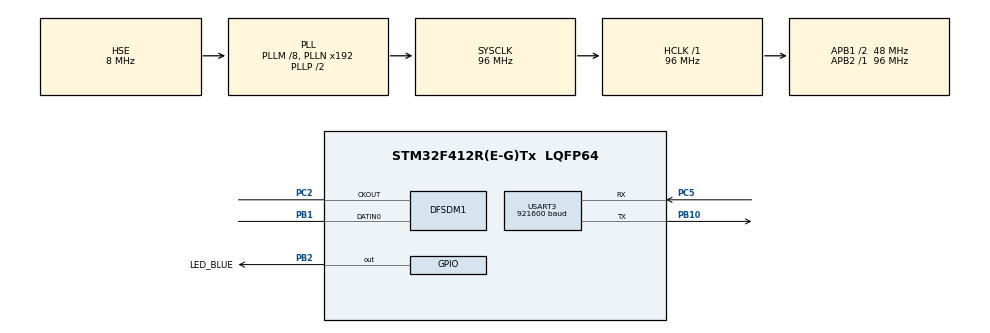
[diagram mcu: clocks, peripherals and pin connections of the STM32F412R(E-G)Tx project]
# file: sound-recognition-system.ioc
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DFSDM1.Divider=30
DFSDM1.DmaMode_reg_FIL0=ENABLE
DFSDM1.FastMode_reg_FIL0=ENABLE
DFSDM1.FilterOrder_CH0=DFSDM_CHANNEL_SINC3_ORDER
DFSDM1.Filter_injChannel0_FIL0=__NULL
DFSDM1.Filter_regChannel_FIL0=DFSDM_CHANNEL_0
DFSDM1.Fosr_FIL0=40
DFSDM1.Iosr_FIL0=5
DFSDM1.RightBitShift_CH0=0x2
DFSDM1.Selection=DFSDM_CHANNEL_OUTPUT_CLOCK_SYSTEM
DFSDM1.SincOrder_FIL0=DFSDM_FILTER_SINC3_ORDER
Dma.DFSDM1_FLT0.0.Direction=DMA_PERIPH_TO_MEMORY
Dma.DFSDM1_FLT0.0.FIFOMode=DMA_FIFOMODE_DISABLE
Dma.DFSDM1_FLT0.0.Instance=DMA2_Stream0
Dma.DFSDM1_FLT0.0.MemDataAlignment=DMA_MDATAALIGN_WORD
Dma.DFSDM1_FLT0.0.MemInc=DMA_MINC_ENABLE
Dma.DFSDM1_FLT0.0.Mode=DMA_CIRCULAR
Dma.DFSDM1_FLT0.0.PeriphDataAlignment=DMA_PDATAALIGN_WORD
Dma.DFSDM1_FLT0.0.PeriphInc=DMA_PINC_DISABLE
Dma.DFSDM1_FLT0.0.Priority=DMA_PRIORITY_VERY_HIGH
Dma.Request0=DFSDM1_FLT0
Dma.Request1=USART3_TX
Dma.USART3_TX.1.Direction=DMA_MEMORY_TO_PERIPH
Dma.USART3_TX.1.FIFOMode=DMA_FIFOMODE_DISABLE
Dma.USART3_TX.1.Instance=DMA1_Stream3
Dma.USART3_TX.1.MemDataAlignment=DMA_MDATAALIGN_BYTE
Dma.USART3_TX.1.MemInc=DMA_MINC_ENABLE
Dma.USART3_TX.1.Mode=DMA_NORMAL
Dma.USART3_TX.1.PeriphDataAlignment=DMA_PDATAALIGN_BYTE
Dma.USART3_TX.1.PeriphInc=DMA_PINC_DISABLE
Dma.USART3_TX.1.Priority=DMA_PRIORITY_LOW
Mcu.Family=STM32F4
Mcu.Name=STM32F412R(E-G)Tx
Mcu.Package=LQFP64
NVIC.DFSDM1_FLT0_IRQn=true\:1\:0\:true\:false\:true\:true\:true\:true
NVIC.DMA1_Stream3_IRQn=true\:5\:0\:true\:false\:true\:false\:true\:true
NVIC.DMA2_Stream0_IRQn=true\:0\:0\:true\:false\:true\:false\:true\:true
NVIC.PriorityGroup=NVIC_PRIORITYGROUP_4
NVIC.USART3_IRQn=true\:6\:0\:true\:false\:true\:false\:true\:true
PA13.Mode=Serial_Wire
PA13.Signal=SYS_JTMS-SWDIO
PA14.Mode=Serial_Wire
PA14.Signal=SYS_JTCK-SWCLK
PB1.Signal=S_DATAIN0DFSDM1
PB10.Mode=Asynchronous
PB10.Signal=USART3_TX
PB2.GPIO_Label=LED_BLUE
PB2.Signal=GPIO_Output
PC14-OSC32_IN.Mode=LSE-External-Oscillator
PC14-OSC32_IN.Signal=RCC_OSC32_IN
PC15-OSC32_OUT.Mode=LSE-External-Oscillator
PC15-OSC32_OUT.Signal=RCC_OSC32_OUT
PC2.GPIO_PuPd=GPIO_NOPULL
PC2.GPIO_Speed=GPIO_SPEED_FREQ_MEDIUM
PC2.Signal=S_CKOUTDFSDM1
PC5.Mode=Asynchronous
PC5.Signal=USART3_RX
PH0\ -\ OSC_IN.Mode=HSE-External-Oscillator
PH0\ -\ OSC_IN.Signal=RCC_OSC_IN
PH1\ -\ OSC_OUT.Mode=HSE-External-Oscillator
PH1\ -\ OSC_OUT.Signal=RCC_OSC_OUT
ProjectManager.HeapSize=0x200
ProjectManager.StackSize=0x400
ProjectManager.TargetToolchain=STM32CubeIDE
RCC.AHBFreq_Value=96000000
RCC.APB1CLKDivider=RCC_HCLK_DIV2
RCC.APB1Freq_Value=48000000
RCC.APB1TimFreq_Value=96000000
RCC.APB2Freq_Value=96000000
RCC.APB2TimFreq_Value=96000000
RCC.CortexFreq_Value=96000000
RCC.EnbaleCSS=true
RCC.HCLKFreq_Value=96000000
RCC.HSE_VALUE=8000000
RCC.PLLI2SM=8
RCC.PLLM=8
RCC.PLLQ=4
RCC.PLLSourceVirtual=RCC_PLLSOURCE_HSE
RCC.RCC_RTC_Clock_Source=RCC_RTCCLKSOURCE_LSE
RCC.RCC_RTC_Clock_SourceVirtual=RCC_RTCCLKSOURCE_LSE
RCC.SYSCLKFreq_VALUE=96000000
RCC.SYSCLKSource=RCC_SYSCLKSOURCE_PLLCLK
RCC.USBFreq_Value=48000000
RCC.VCOOutputFreq_Value=192000000
SH.S_CKOUTDFSDM1.0=DFSDM1_CKOUT,CKOUT
SH.S_CKOUTDFSDM1.1=DFSDM1_CKOUT,PDM_SPI_input_from_ch0_and_internal_clock
SH.S_DATAIN0DFSDM1.0=DFSDM1_DATIN0,PDM_SPI_input_from_ch0_and_internal_clock
USART3.BaudRate=921600
USART3.Mode=MODE_TX_RX
USART3.VirtualMode=VM_ASYNC
VP_CRC_VS_CRC.Mode=CRC_Activate
VP_RTC_VS_RTC_Activate.Mode=RTC_Enabled
VP_RTC_VS_RTC_Calendar.Mode=RTC_Calendar
board=custom

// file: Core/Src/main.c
/* USER CODE BEGIN Header */
/**
  ******************************************************************************
  * @file           : main.c
  * @brief          : Main program body
  ******************************************************************************
  * @attention
  *
  * Copyright (c) 2026 STMicroelectronics.
  * All rights reserved.
  *
  * This software is licensed under terms that can be found in the LICENSE file
  * in the root directory of this software component.
  * If no LICENSE file comes with this software, it is provided AS-IS.
  *
  ******************************************************************************
  */
/* USER CODE END Header */
#include "main.h"
#include "app.h"
#include "indicator.h"

/* USER CODE BEGIN PD */
#define RTC_BACKUP_MAGIC 0x32F2U

/* USER CODE END PD */

CRC_HandleTypeDef hcrc;

DFSDM_Filter_HandleTypeDef hdfsdm1_filter0;
DFSDM_Channel_HandleTypeDef hdfsdm1_channel0;
DMA_HandleTypeDef hdma_dfsdm1_flt0;

RTC_HandleTypeDef hrtc;

UART_HandleTypeDef huart3;
DMA_HandleTypeDef hdma_usart3_tx;

void SystemClock_Config(void);
static void MX_GPIO_Init(void);
static void MX_DMA_Init(void);
static void MX_DFSDM1_Init(void);
static void MX_RTC_Init(void);
static void MX_USART3_UART_Init(void);
static void MX_CRC_Init(void);

int main(void) {

    /* MCU Configuration--------------------------------------------------------*/

    /* Reset of all peripherals, Initializes the Flash interface and the Systick. */
    HAL_Init();

    /* Configure the system clock */
    SystemClock_Config();

    /* Initialize all configured peripherals */
    MX_GPIO_Init();
    MX_DMA_Init();
    MX_DFSDM1_Init();
    MX_RTC_Init();
    MX_USART3_UART_Init();
    MX_CRC_Init();
    /* USER CODE BEGIN 2 */
    app_run();
    /* USER CODE END 2 */

    /* Infinite loop */
    while (1) {

    }
}

void SystemClock_Config(void) {
    RCC_OscInitTypeDef RCC_OscInitStruct = {0};
    RCC_ClkInitTypeDef RCC_ClkInitStruct = {0};

    /** Configure the main internal regulator output voltage
    */
    __HAL_RCC_PWR_CLK_ENABLE();
    __HAL_PWR_VOLTAGESCALING_CONFIG(PWR_REGULATOR_VOLTAGE_SCALE1);

    /** Initializes the RCC Oscillators according to the specified parameters
    * in the RCC_OscInitTypeDef structure.
    */
    RCC_OscInitStruct.OscillatorType = RCC_OSCILLATORTYPE_HSE | RCC_OSCILLATORTYPE_LSE;
    RCC_OscInitStruct.HSEState = RCC_HSE_ON;
    RCC_OscInitStruct.LSEState = RCC_LSE_ON;
    RCC_OscInitStruct.PLL.PLLState = RCC_PLL_ON;
    RCC_OscInitStruct.PLL.PLLSource = RCC_PLLSOURCE_HSE;
    RCC_OscInitStruct.PLL.PLLM = 8;
    RCC_OscInitStruct.PLL.PLLN = 192;
    RCC_OscInitStruct.PLL.PLLP = RCC_PLLP_DIV2;
    RCC_OscInitStruct.PLL.PLLQ = 4;
    RCC_OscInitStruct.PLL.PLLR = 2;
    if (HAL_RCC_OscConfig(&RCC_OscInitStruct) != HAL_OK) {
        Error_Handler();
    }

    /** Initializes the CPU, AHB and APB buses clocks
    */
    RCC_ClkInitStruct.ClockType = RCC_CLOCKTYPE_HCLK | RCC_CLOCKTYPE_SYSCLK
                                  | RCC_CLOCKTYPE_PCLK1 | RCC_CLOCKTYPE_PCLK2;
    RCC_ClkInitStruct.SYSCLKSource = RCC_SYSCLKSOURCE_PLLCLK;
    RCC_ClkInitStruct.AHBCLKDivider = RCC_SYSCLK_DIV1;
    RCC_ClkInitStruct.APB1CLKDivider = RCC_HCLK_DIV2;
    RCC_ClkInitStruct.APB2CLKDivider = RCC_HCLK_DIV1;

    if (HAL_RCC_ClockConfig(&RCC_ClkInitStruct, FLASH_LATENCY_3) != HAL_OK) {
        Error_Handler();
    }

    /** Enables the Clock Security System
    */
    HAL_RCC_EnableCSS();
}

static void MX_CRC_Init(void) {

    hcrc.Instance = CRC;
    if (HAL_CRC_Init(&hcrc) != HAL_OK) {
        Error_Handler();
    }
}

static void MX_DFSDM1_Init(void) {

    hdfsdm1_filter0.Instance = DFSDM1_Filter0;
    hdfsdm1_filter0.Init.RegularParam.Trigger = DFSDM_FILTER_SW_TRIGGER;
    hdfsdm1_filter0.Init.RegularParam.FastMode = ENABLE;
    hdfsdm1_filter0.Init.RegularParam.DmaMode = ENABLE;
    hdfsdm1_filter0.Init.FilterParam.SincOrder = DFSDM_FILTER_SINC3_ORDER;
    hdfsdm1_filter0.Init.FilterParam.Oversampling = 40;
    hdfsdm1_filter0.Init.FilterParam.IntOversampling = 5;
    if (HAL_DFSDM_FilterInit(&hdfsdm1_filter0) != HAL_OK) {
        Error_Handler();
    }
    hdfsdm1_channel0.Instance = DFSDM1_Channel0;
    hdfsdm1_channel0.Init.OutputClock.Activation = ENABLE;
    hdfsdm1_channel0.Init.OutputClock.Selection = DFSDM_CHANNEL_OUTPUT_CLOCK_SYSTEM;
    hdfsdm1_channel0.Init.OutputClock.Divider = 30;
    hdfsdm1_channel0.Init.Input.Multiplexer = DFSDM_CHANNEL_EXTERNAL_INPUTS;
    hdfsdm1_channel0.Init.Input.DataPacking = DFSDM_CHANNEL_STANDARD_MODE;
    hdfsdm1_channel0.Init.Input.Pins = DFSDM_CHANNEL_SAME_CHANNEL_PINS;
    hdfsdm1_channel0.Init.SerialInterface.Type = DFSDM_CHANNEL_SPI_RISING;
    hdfsdm1_channel0.Init.SerialInterface.SpiClock = DFSDM_CHANNEL_SPI_CLOCK_INTERNAL;
    hdfsdm1_channel0.Init.Awd.FilterOrder = DFSDM_CHANNEL_SINC3_ORDER;
    hdfsdm1_channel0.Init.Awd.Oversampling = 1;
    hdfsdm1_channel0.Init.Offset = 0;
    hdfsdm1_channel0.Init.RightBitShift = 0x2;
    if (HAL_DFSDM_ChannelInit(&hdfsdm1_channel0) != HAL_OK) {
        Error_Handler();
    }
    if (HAL_DFSDM_FilterConfigRegChannel(&hdfsdm1_filter0, DFSDM_CHANNEL_0, DFSDM_CONTINUOUS_CONV_ON) != HAL_OK) {
        Error_Handler();
    }
}

static void MX_RTC_Init(void) {

    RTC_TimeTypeDef sTime = {0};
    RTC_DateTypeDef sDate = {0};

    /** Initialize RTC Only
    */
    hrtc.Instance = RTC;
    hrtc.Init.HourFormat = RTC_HOURFORMAT_24;
    hrtc.Init.AsynchPrediv = 127;
    hrtc.Init.SynchPrediv = 255;
    hrtc.Init.OutPut = RTC_OUTPUT_DISABLE;
    hrtc.Init.OutPutPolarity = RTC_OUTPUT_POLARITY_HIGH;
    hrtc.Init.OutPutType = RTC_OUTPUT_TYPE_OPENDRAIN;
    if (HAL_RTC_Init(&hrtc) != HAL_OK) {
        Error_Handler();
    }

    /* USER CODE BEGIN Check_RTC_BKUP */
    if (HAL_RTCEx_BKUPRead(&hrtc, RTC_BKP_DR0) != RTC_BACKUP_MAGIC) {
        /* USER CODE END Check_RTC_BKUP */

        /** Initialize RTC and set the Time and Date
        */
        sTime.Hours = 0x0;
        sTime.Minutes = 0x0;
        sTime.Seconds = 0x0;
        sTime.DayLightSaving = RTC_DAYLIGHTSAVING_NONE;
        sTime.StoreOperation = RTC_STOREOPERATION_RESET;
        if (HAL_RTC_SetTime(&hrtc, &sTime, RTC_FORMAT_BCD) != HAL_OK) {
            Error_Handler();
        }
        sDate.WeekDay = RTC_WEEKDAY_MONDAY;
        sDate.Month = RTC_MONTH_JANUARY;
        sDate.Date = 0x1;
        sDate.Year = 0x0;

        if (HAL_RTC_SetDate(&hrtc, &sDate, RTC_FORMAT_BCD) != HAL_OK) {
            Error_Handler();
        }
        /* USER CODE BEGIN RTC_Init 2 */
        HAL_RTCEx_BKUPWrite(&hrtc, RTC_BKP_DR0, RTC_BACKUP_MAGIC);
    }

    /* USER CODE END RTC_Init 2 */
}

static void MX_USART3_UART_Init(void) {

    huart3.Instance = USART3;
    huart3.Init.BaudRate = 921600;
    huart3.Init.WordLength = UART_WORDLENGTH_8B;
    huart3.Init.StopBits = UART_STOPBITS_1;
    huart3.Init.Parity = UART_PARITY_NONE;
    huart3.Init.Mode = UART_MODE_TX_RX;
    huart3.Init.HwFlowCtl = UART_HWCONTROL_NONE;
    huart3.Init.OverSampling = UART_OVERSAMPLING_16;
    if (HAL_UART_Init(&huart3) != HAL_OK) {
        Error_Handler();
    }
}

static void MX_DMA_Init(void) {
    /* DMA controller clock enable */
    __HAL_RCC_DMA2_CLK_ENABLE();
    __HAL_RCC_DMA1_CLK_ENABLE();

    /* DMA interrupt init */
    /* DMA1_Stream3_IRQn interrupt configuration */
    HAL_NVIC_SetPriority(DMA1_Stream3_IRQn, 5, 0);
    HAL_NVIC_EnableIRQ(DMA1_Stream3_IRQn);
    /* DMA2_Stream0_IRQn interrupt configuration */
    HAL_NVIC_SetPriority(DMA2_Stream0_IRQn, 0, 0);
    HAL_NVIC_EnableIRQ(DMA2_Stream0_IRQn);
}

static void MX_GPIO_Init(void) {
    GPIO_InitTypeDef GPIO_InitStruct = {0};

    /* GPIO Ports Clock Enable */
    __HAL_RCC_GPIOC_CLK_ENABLE();
    __HAL_RCC_GPIOH_CLK_ENABLE();
    __HAL_RCC_GPIOB_CLK_ENABLE();
    __HAL_RCC_GPIOA_CLK_ENABLE();

    /*Configure GPIO pin Output Level */
    HAL_GPIO_WritePin(LED_BLUE_GPIO_Port, LED_BLUE_Pin, GPIO_PIN_RESET);

    /*Configure GPIO pin : LED_BLUE_Pin */
    GPIO_InitStruct.Pin = LED_BLUE_Pin;
    GPIO_InitStruct.Mode = GPIO_MODE_OUTPUT_PP;
    GPIO_InitStruct.Pull = GPIO_NOPULL;
    GPIO_InitStruct.Speed = GPIO_SPEED_FREQ_LOW;
    HAL_GPIO_Init(LED_BLUE_GPIO_Port, &GPIO_InitStruct);

}

void Error_Handler(void) {
    __disable_irq();
    while (1) {
    }
}
